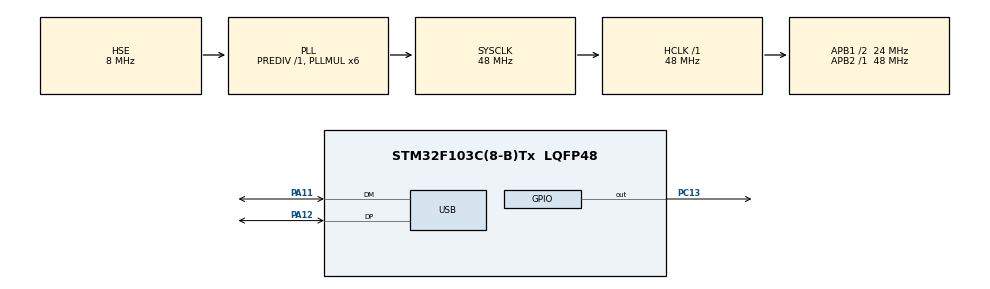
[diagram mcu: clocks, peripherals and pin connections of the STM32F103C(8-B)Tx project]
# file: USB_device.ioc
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Mcu.Family=STM32F1
Mcu.Name=STM32F103C(8-B)Tx
Mcu.Package=LQFP48
NVIC.PriorityGroup=NVIC_PRIORITYGROUP_4
NVIC.USB_HP_CAN1_TX_IRQn=true\:0\:0\:false\:false\:true\:true\:true
NVIC.USB_LP_CAN1_RX0_IRQn=true\:0\:0\:false\:false\:true\:false\:true
PA11.Mode=Device
PA11.Signal=USB_DM
PA12.Mode=Device
PA12.Signal=USB_DP
PC13-TAMPER-RTC.Signal=GPIO_Output
PC14-OSC32_IN.Mode=LSE-External-Oscillator
PC14-OSC32_IN.Signal=RCC_OSC32_IN
PC15-OSC32_OUT.Mode=LSE-External-Oscillator
PC15-OSC32_OUT.Signal=RCC_OSC32_OUT
PD0-OSC_IN.Mode=HSE-External-Oscillator
PD0-OSC_IN.Signal=RCC_OSC_IN
PD1-OSC_OUT.Mode=HSE-External-Oscillator
PD1-OSC_OUT.Signal=RCC_OSC_OUT
ProjectManager.HeapSize=0x200
ProjectManager.StackSize=0x400
ProjectManager.TargetToolchain=STM32CubeIDE
RCC.AHBFreq_Value=48000000
RCC.APB1CLKDivider=RCC_HCLK_DIV2
RCC.APB1Freq_Value=24000000
RCC.APB1TimFreq_Value=48000000
RCC.APB2Freq_Value=48000000
RCC.APB2TimFreq_Value=48000000
RCC.HCLKFreq_Value=48000000
RCC.PLLMUL=RCC_PLL_MUL6
RCC.SYSCLKFreq_VALUE=48000000
RCC.SYSCLKSource=RCC_SYSCLKSOURCE_PLLCLK
RCC.USBFreq_Value=48000000
USB_DEVICE.CLASS_NAME_FS=CDC
USB_DEVICE.USBD_MAX_STR_DESC_SIZ=256
USB_DEVICE.VirtualMode=Cdc
USB_DEVICE.VirtualModeFS=Cdc_FS
VP_SYS_VS_ND.Mode=No_Debug
VP_USB_DEVICE_VS_USB_DEVICE_CDC_FS.Mode=CDC_FS
board=custom

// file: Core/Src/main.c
/* USER CODE BEGIN Header */
/**
  ******************************************************************************
  * @file           : main.c
  * @brief          : Main program body
  ******************************************************************************
  * @attention
  *
  * <h2><center>&copy; Copyright (c) 2020 STMicroelectronics.
  * All rights reserved.</center></h2>
  *
  * This software component is licensed by ST under BSD 3-Clause license,
  * the "License"; You may not use this file except in compliance with the
  * License. You may obtain a copy of the License at:
  *                        opensource.org/licenses/BSD-3-Clause
  *
  ******************************************************************************
  */
/* USER CODE END Header */
#include "main.h"
#include "usb_device.h"

/* USER CODE BEGIN Includes */
#include "commands.h"
/* USER CODE END Includes */

void SystemClock_Config(void);
static void MX_GPIO_Init(void);

/* USER CODE BEGIN 0 */
uint8_t UserRXbuffer[16];
uint8_t haveDataToParse = 0;
uint8_t data[1000];
uint8_t startSymbol = 255;
uint8_t stopSymbol = 254;
/* USER CODE END 0 */

int main(void)
{
  /* USER CODE BEGIN 1 */
	for(int x = 0; x < 1000; x++) {
		  data[x] = (int) (150 * (exp(-(x - 100) * (x - 100) / 50 ) + exp(-(x - 700) * (x - 700) / 20000  ) ));
	  }
  /* USER CODE END 1 */

  /* MCU Configuration--------------------------------------------------------*/

  /* Reset of all peripherals, Initializes the Flash interface and the Systick. */
  HAL_Init();

  /* Configure the system clock */
  SystemClock_Config();

  /* Initialize all configured peripherals */
  MX_GPIO_Init();
  MX_USB_DEVICE_Init();
  /* USER CODE BEGIN 2 */
  uint8_t count = 0;
  /* USER CODE END 2 */

  /* Infinite loop */
  /* USER CODE BEGIN WHILE */
  while (1)
  {
	  //HAL_Delay(0 + rand() % 3);
	  if(haveDataToParse) {

		  if(UserRXbuffer[0] == 'r') {
			  while(CDC_Transmit_FS(&startSymbol, 1) == USBD_BUSY);
			  //HAL_Delay(0 + rand() % 3);
			  while(CDC_Transmit_FS(&data, 1000) == USBD_BUSY);
			  //HAL_Delay(0 + rand() % 3);
			  while(CDC_Transmit_FS(&stopSymbol, 1) == USBD_BUSY);
		  }

		  if(UserRXbuffer[0] == 'a') {
			  //HAL_Delay(0 + rand() % 3);
			  for(int x = 0; x < 1000; x++) {
			 		  data[x] = count;//(int) (1 + rand() % 10 + 150 * (exp(-(x - 100) * (x - 100) / 50 ) + exp(-(x - 700) * (x - 700) / 20000  ) ));
			 	  }
			  HAL_GPIO_TogglePin(GPIOC, GPIO_PIN_13);
			  count++;
		  }

		  haveDataToParse = 0;
	  }
    /* USER CODE END WHILE */

  }
}

void SystemClock_Config(void)
{
  RCC_OscInitTypeDef RCC_OscInitStruct = {0};
  RCC_ClkInitTypeDef RCC_ClkInitStruct = {0};
  RCC_PeriphCLKInitTypeDef PeriphClkInit = {0};

  /** Initializes the RCC Oscillators according to the specified parameters
  * in the RCC_OscInitTypeDef structure.
  */
  RCC_OscInitStruct.OscillatorType = RCC_OSCILLATORTYPE_HSE;
  RCC_OscInitStruct.HSEState = RCC_HSE_ON;
  RCC_OscInitStruct.HSEPredivValue = RCC_HSE_PREDIV_DIV1;
  RCC_OscInitStruct.HSIState = RCC_HSI_ON;
  RCC_OscInitStruct.PLL.PLLState = RCC_PLL_ON;
  RCC_OscInitStruct.PLL.PLLSource = RCC_PLLSOURCE_HSE;
  RCC_OscInitStruct.PLL.PLLMUL = RCC_PLL_MUL6;
  if (HAL_RCC_OscConfig(&RCC_OscInitStruct) != HAL_OK)
  {
    Error_Handler();
  }
  /** Initializes the CPU, AHB and APB buses clocks
  */
  RCC_ClkInitStruct.ClockType = RCC_CLOCKTYPE_HCLK|RCC_CLOCKTYPE_SYSCLK
                              |RCC_CLOCKTYPE_PCLK1|RCC_CLOCKTYPE_PCLK2;
  RCC_ClkInitStruct.SYSCLKSource = RCC_SYSCLKSOURCE_PLLCLK;
  RCC_ClkInitStruct.AHBCLKDivider = RCC_SYSCLK_DIV1;
  RCC_ClkInitStruct.APB1CLKDivider = RCC_HCLK_DIV2;
  RCC_ClkInitStruct.APB2CLKDivider = RCC_HCLK_DIV1;

  if (HAL_RCC_ClockConfig(&RCC_ClkInitStruct, FLASH_LATENCY_1) != HAL_OK)
  {
    Error_Handler();
  }
  PeriphClkInit.PeriphClockSelection = RCC_PERIPHCLK_USB;
  PeriphClkInit.UsbClockSelection = RCC_USBCLKSOURCE_PLL;
  if (HAL_RCCEx_PeriphCLKConfig(&PeriphClkInit) != HAL_OK)
  {
    Error_Handler();
  }
}

static void MX_GPIO_Init(void)
{
  GPIO_InitTypeDef GPIO_InitStruct = {0};

  /* GPIO Ports Clock Enable */
  __HAL_RCC_GPIOC_CLK_ENABLE();
  __HAL_RCC_GPIOD_CLK_ENABLE();
  __HAL_RCC_GPIOA_CLK_ENABLE();

  /*Configure GPIO pin Output Level */
  HAL_GPIO_WritePin(GPIOC, GPIO_PIN_13, GPIO_PIN_RESET);

  /*Configure GPIO pin : PC13 */
  GPIO_InitStruct.Pin = GPIO_PIN_13;
  GPIO_InitStruct.Mode = GPIO_MODE_OUTPUT_PP;
  GPIO_InitStruct.Pull = GPIO_NOPULL;
  GPIO_InitStruct.Speed = GPIO_SPEED_FREQ_LOW;
  HAL_GPIO_Init(GPIOC, &GPIO_InitStruct);

}

/* USER CODE BEGIN 4 */
void CDC_Recive_Callback(uint8_t* Buf, uint16_t* len) {
	memcpy(&UserRXbuffer, Buf, 16);

	haveDataToParse = 1;
}
/* USER CODE END 4 */

void Error_Handler(void)
{
}

/************************ (C) COPYRIGHT STMicroelectronics *****END OF FILE****/
